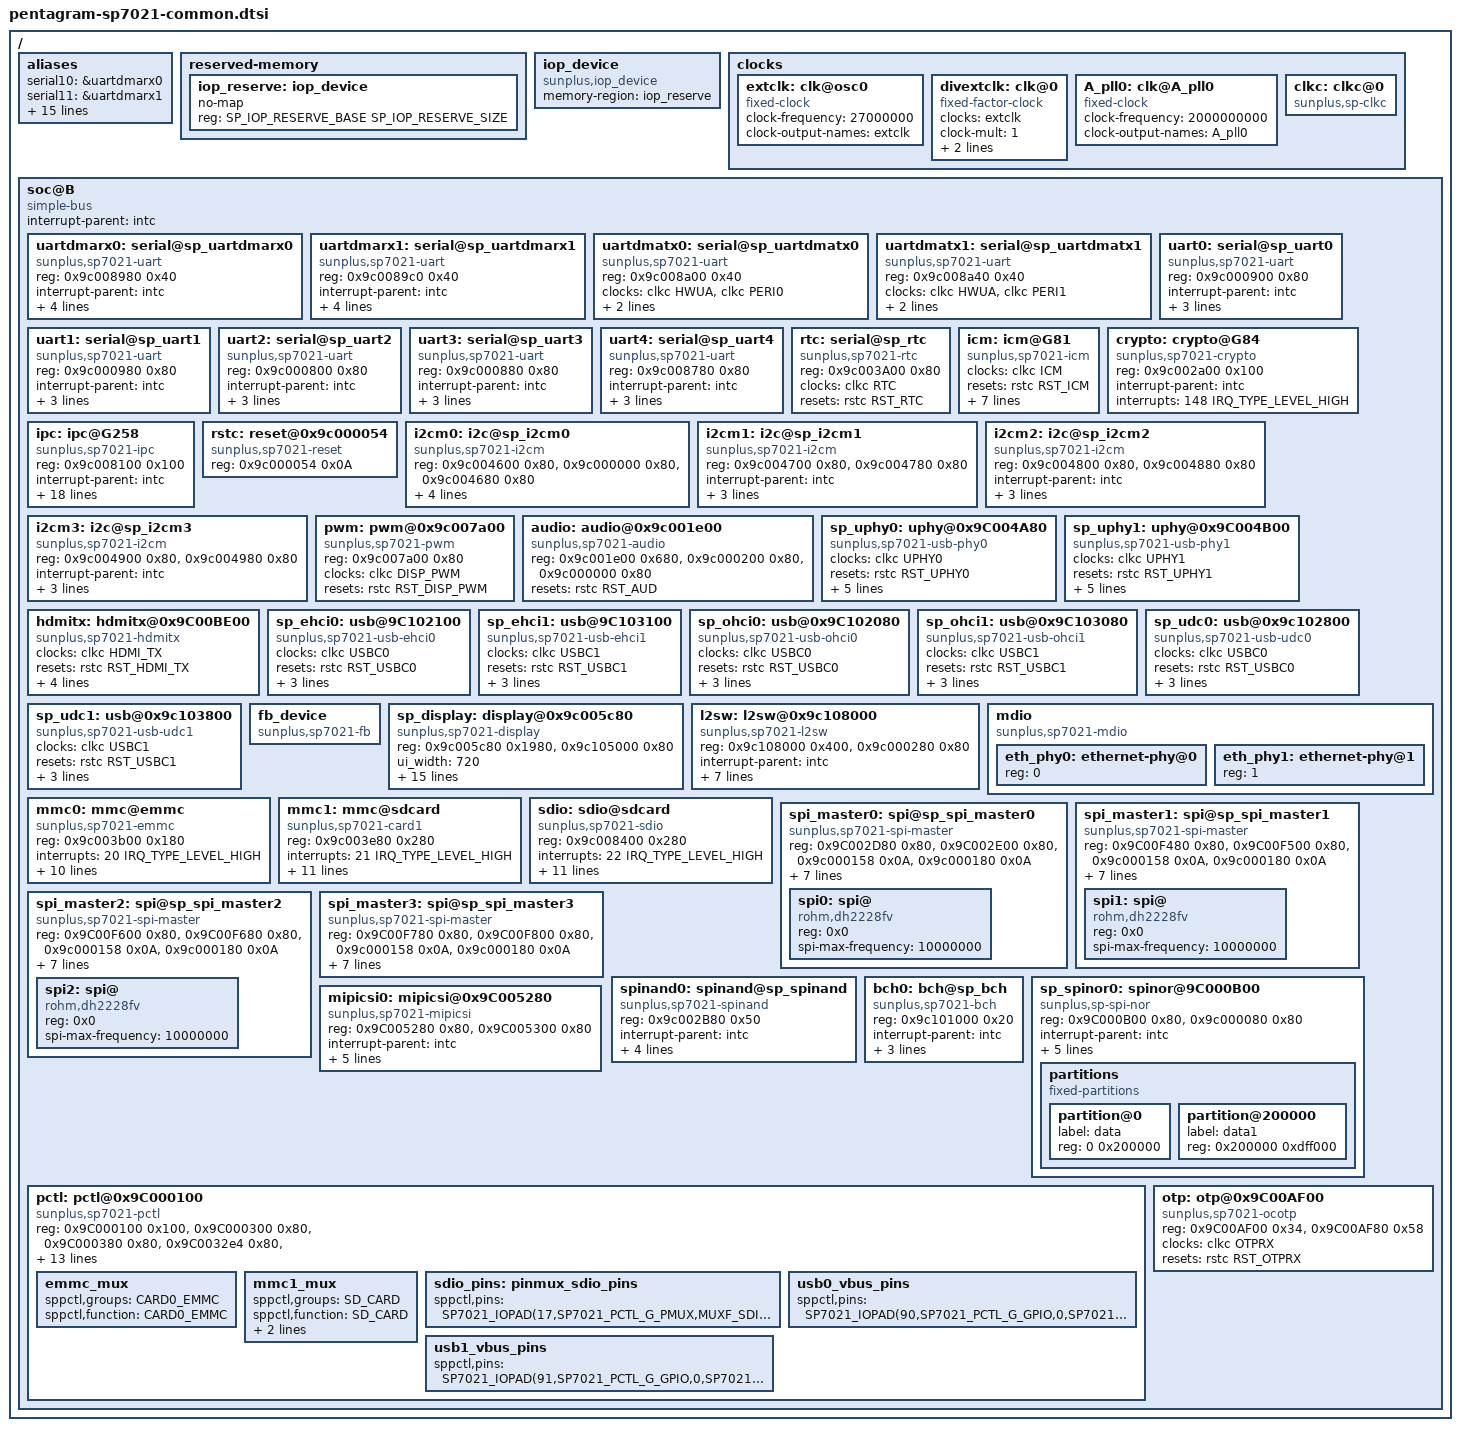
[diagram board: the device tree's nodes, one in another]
/dts-v1/;

#include "pentagram-sp7021-storage.dtsi"

#include <dt-bindings/clock/sp-q628.h>
#include <dt-bindings/memory/sp-q628-mem.h>
#include <dt-bindings/interrupt-controller/arm-gic.h>
#include <dt-bindings/interrupt-controller/sp-intc.h> /* SP_INTC_EXT_INT1 */
#include <dt-bindings/reset/sp-q628.h>
#include <dt-bindings/gpio/gpio.h>
#include <dt-bindings/pinctrl/sp7021.h>

#define ENABLE_DMARX0
#define ENABLE_DMARX1
#define ENABLE_DMATX0
#define ENABLE_DMATX1

/ {
	aliases {
#ifdef ENABLE_DMARX0
		serial10 = &uartdmarx0;
#endif
#ifdef ENABLE_DMARX1
		serial11 = &uartdmarx1;
#endif
#ifdef ENABLE_DMATX0
		serial20 = &uartdmatx0;
#endif
#ifdef ENABLE_DMATX1
		serial21 = &uartdmatx1;
#endif

		serial0 = &uart0;
		serial1 = &uart1;
		serial2 = &uart2;
		serial3 = &uart3;
		serial4 = &uart4;

/* Timer tests: */
/* 1. Enable device tree for timers. */
/* 2. Enable sp_timer_test in drivers/misc/Makefile */
#if 0

		stc0 = &sp_tmr_tst0;
		stc1 = &sp_tmr_tst1;
		stc2 = &sp_tmr_tst2;
		stc3 = &sp_tmr_tst3;

#endif

		i2c0 = &i2cm0;
		i2c1 = &i2cm1;
		i2c2 = &i2cm2;
		i2c3 = &i2cm3;

		spi0 = &spi_master0;
		spi1 = &spi_master1;
		spi2 = &spi_master2;
		spi3 = &spi_master3;

	};

	reserved-memory {
		#address-cells = <1>;
		#size-cells = <1>;
		ranges;

		iop_reserve: iop_device {
			no-map;
			reg = <SP_IOP_RESERVE_BASE SP_IOP_RESERVE_SIZE>;
		};
	};

	iop_device {
		compatible = "sunplus,iop_device";
		memory-region = <&iop_reserve>;
	};

	clocks {
		#address-cells = <1>;
		#size-cells = <1>;
		ranges;

		extclk: clk@osc0 {
			#clock-cells = <0>;
			compatible = "fixed-clock";
			clock-frequency = <27000000>;
			clock-output-names = "extclk";
		};

		divextclk: clk@0 {
			#clock-cells = <0>;
			compatible = "fixed-factor-clock";
			clocks  = <&extclk>;
			clock-mult = <1>;
			clock-div = <2>;
			clock-output-names = "extdivclk";
		};

		A_pll0: clk@A_pll0 {
			#clock-cells = <0>;
			compatible = "fixed-clock";
			clock-frequency = <2000000000>;
			clock-output-names = "A_pll0";
		};

		clkc: clkc@0 {
			#clock-cells = <1>;
			compatible = "sunplus,sp-clkc";
		};
	};

	soc@B {
		compatible = "simple-bus";
		#address-cells = <1>;
		#size-cells = <1>;
		ranges;

		interrupt-parent = <&intc>;

		/* B modules */
#if  0
		intc: interrupt-controller@G15 {
			compatible = "sunplus,sp-intc";
			interrupt-controller;
			#interrupt-cells = <2>;
			reg = <0x9c000780 0x80>, /* G15 */
			      <0x9c000a80 0x80>; /* G21 */
			interrupt-parent = <&gic>;
			interrupts = <GIC_SPI 5 IRQ_TYPE_LEVEL_HIGH>, /* EXT_INT0 */
				     <GIC_SPI 6 IRQ_TYPE_LEVEL_HIGH>; /* EXT_INT1 */
			ext0-mask = <0xf>; /* core0-3 */
			ext1-mask = <0xe>; /* core1-3 */
		};
#endif

#ifdef ENABLE_DMARX0
		/* DMA Rx for UARTx */
		uartdmarx0: serial@sp_uartdmarx0 {
			compatible = "sunplus,sp7021-uart";
			reg = <0x9c008980 0x40>;
			interrupt-parent = <&intc>;
			interrupts = <138 IRQ_TYPE_LEVEL_HIGH>;
			clocks = <&clkc UADMA>,
				 <&clkc PERI0>;
			clock-names = "UADMA",
				      "PERI0";
			resets = <&rstc RST_UADMA>;
			which-uart = <1>;
		};
#endif
#ifdef ENABLE_DMARX1
		uartdmarx1: serial@sp_uartdmarx1 {
			compatible = "sunplus,sp7021-uart";
			reg = <0x9c0089c0 0x40>;
			interrupt-parent = <&intc>;
			interrupts = <139 IRQ_TYPE_LEVEL_HIGH>;
			clocks = <&clkc UADMA>,
				 <&clkc PERI1>;
			clock-names = "UADMA",
				      "PERI1";
			resets = <&rstc RST_UADMA>;
			which-uart = <2>;
		};
#endif
#ifdef ENABLE_DMATX0
		/* DMA Tx for UARTx */
		uartdmatx0: serial@sp_uartdmatx0 {
			compatible = "sunplus,sp7021-uart";
			reg = <0x9c008a00 0x40>;
			clocks = <&clkc HWUA>,
				 <&clkc PERI0>;
			clock-names = "HWUA",
				      "PERI0";
			resets = <&rstc RST_UADMA>;
			which-uart = <1>;
		};
#endif
#ifdef ENABLE_DMATX1
		uartdmatx1: serial@sp_uartdmatx1 {
			compatible = "sunplus,sp7021-uart";
			reg = <0x9c008a40 0x40>;
			clocks = <&clkc HWUA>,
				 <&clkc PERI1>;
			clock-names = "HWUA",
				      "PERI1";
			resets = <&rstc RST_UADMA>;
			which-uart = <2>;
		};
#endif

		uart0: serial@sp_uart0 {
			compatible = "sunplus,sp7021-uart";
			reg = <0x9c000900 0x80>;
			interrupt-parent = <&intc>;
			interrupts = <53 IRQ_TYPE_LEVEL_HIGH>;
			clocks = <&clkc UA0>;
			resets = <&rstc RST_UA0>;
		};

		uart1: serial@sp_uart1 {
			compatible = "sunplus,sp7021-uart";
			reg = <0x9c000980 0x80>;
			interrupt-parent = <&intc>;
			interrupts = <54 IRQ_TYPE_LEVEL_HIGH>;
			clocks = <&clkc UA1>;
			resets = <&rstc RST_UA1>;
		};

		uart2: serial@sp_uart2 {
			compatible = "sunplus,sp7021-uart";
			reg = <0x9c000800 0x80>;
			interrupt-parent = <&intc>;
			interrupts = <55 IRQ_TYPE_LEVEL_HIGH>;
			clocks = <&clkc UA2>;
			resets = <&rstc RST_UA2>;
		};

		uart3: serial@sp_uart3 {
			compatible = "sunplus,sp7021-uart";
			reg = <0x9c000880 0x80>;
			interrupt-parent = <&intc>;
			interrupts = <56 IRQ_TYPE_LEVEL_HIGH>;
			clocks = <&clkc UA3>;
			resets = <&rstc RST_UA3>;
		};

		uart4: serial@sp_uart4 {
			compatible = "sunplus,sp7021-uart";
			reg = <0x9c008780 0x80>;
			interrupt-parent = <&intc>;
			interrupts = <134 IRQ_TYPE_LEVEL_HIGH>;
			clocks = <&clkc UA4>;
			resets = <&rstc RST_UA4>;
		};



		rtc: serial@sp_rtc {
			compatible = "sunplus,sp7021-rtc";
			reg = <0x9c003A00 0x80>;
			reg-names = "rtc_reg";
			clocks = <&clkc RTC>;
			resets = <&rstc RST_RTC>;
		};



		icm: icm@G81 {
			compatible = "sunplus,sp7021-icm";
			clocks = <&clkc ICM>;
			resets = <&rstc RST_ICM>;
			/* clken format: (group << 16) | (index << 8) | shift */
			clken = <0x00000a08>; /* 0.10.8 */
			reg = <0x9c002880 0x80>;
			interrupt-parent = <&intc>;
			interrupts =
				<92 IRQ_TYPE_EDGE_RISING>, /* icm0 */
				<93 IRQ_TYPE_EDGE_RISING>, /* icm1 */
				<94 IRQ_TYPE_EDGE_RISING>, /* icm2 */
				<95 IRQ_TYPE_EDGE_RISING>; /* icm3 */
		};

		crypto: crypto@G84 {
			compatible = "sunplus,sp7021-crypto";
			reg = <0x9c002a00 0x100>; /* G84 ~ G85 */
			interrupt-parent = <&intc>;
			interrupts = <148 IRQ_TYPE_LEVEL_HIGH>;
		};

		ipc: ipc@G258 {
			compatible = "sunplus,sp7021-ipc";
			reg = <0x9c008100 0x100>; /* G258 ~ G259 */
			interrupt-parent = <&intc>;
			interrupts =
				<182 IRQ_TYPE_EDGE_RISING>, /* ACHIPCPU0_DIRECT_INT0 */
				<183 IRQ_TYPE_EDGE_RISING>, /* ACHIPCPU0_DIRECT_INT1 */
				<184 IRQ_TYPE_EDGE_RISING>, /* ACHIPCPU0_DIRECT_INT2 */
				<185 IRQ_TYPE_EDGE_RISING>, /* ACHIPCPU0_DIRECT_INT3 */
				<186 IRQ_TYPE_EDGE_RISING>, /* ACHIPCPU0_DIRECT_INT4 */
				<187 IRQ_TYPE_EDGE_RISING>, /* ACHIPCPU0_DIRECT_INT5 */
				<188 IRQ_TYPE_EDGE_RISING>, /* ACHIPCPU0_DIRECT_INT6 */
				<189 IRQ_TYPE_EDGE_RISING>, /* ACHIPCPU0_DIRECT_INT7 */
				<190 IRQ_TYPE_EDGE_RISING>, /* A926_DIRECT_INT0 */
				<191 IRQ_TYPE_EDGE_RISING>, /* A926_DIRECT_INT1 */
				<192 IRQ_TYPE_EDGE_RISING>, /* A926_DIRECT_INT2 */
				<193 IRQ_TYPE_EDGE_RISING>, /* A926_DIRECT_INT3 */
				<194 IRQ_TYPE_EDGE_RISING>, /* A926_DIRECT_INT4 */
				<195 IRQ_TYPE_EDGE_RISING>, /* A926_DIRECT_INT5 */
				<196 IRQ_TYPE_EDGE_RISING>, /* A926_DIRECT_INT6 */
				<197 IRQ_TYPE_EDGE_RISING>, /* A926_DIRECT_INT7 */
				<198 IRQ_TYPE_EDGE_RISING>, /* ACHIPCPU0_INT */
				<199 IRQ_TYPE_EDGE_RISING>; /* A926_INT */
		};

/* Timer tests: */
/* 1. Enable device tree for timers. */
/* 2. Enable sp_timer_test in drivers/misc/Makefile */
#if 0
		sp_tmr_tst0: sp_tmr_tst@9c000600 {
			compatible = "sunplus,sp-tmr-tst";
			reg = <0x9c000600 0x80>;
			interrupt-parent = <&intc>;
			interrupts =
				<151 IRQ_TYPE_EDGE_RISING>, /* timer0 */
				<152 IRQ_TYPE_EDGE_RISING>, /* timer1 */
				<153 IRQ_TYPE_EDGE_RISING>, /* timer2 */
				<154 IRQ_TYPE_EDGE_RISING>; /* timer3 */
			clocks = <&clkc STC0>;
			resets = <&rstc RST_STC0>;
		};

		sp_tmr_tst1: sp_tmr_tst@9c003000 {
			compatible = "sunplus,sp-tmr-tst";
			reg = <0x9c003000 0x80>;
			interrupt-parent = <&intc>;
			interrupts =
				<155 IRQ_TYPE_EDGE_RISING>, /* timer0 */
				<156 IRQ_TYPE_EDGE_RISING>, /* timer1 */
				<157 IRQ_TYPE_EDGE_RISING>, /* timer2 */
				<158 IRQ_TYPE_EDGE_RISING>; /* timer3 */
			clocks = <&clkc STC_AV0>;
			resets = <&rstc RST_STC_AV0>;
		};

		sp_tmr_tst2: sp_tmr_tst@9c003080 {
			compatible = "sunplus,sp-tmr-tst";
			reg = <0x9c003080 0x80>;
			interrupt-parent = <&intc>;
			interrupts =
				<159 IRQ_TYPE_EDGE_RISING>, /* timer0 */
				<160 IRQ_TYPE_EDGE_RISING>, /* timer1 */
				<161 IRQ_TYPE_EDGE_RISING>, /* timer2 */
				<162 IRQ_TYPE_EDGE_RISING>; /* timer3 */
			clocks = <&clkc STC_AV1>;
			resets = <&rstc RST_STC_AV1>;
		};

		sp_tmr_tst3: sp_tmr_tst@9c003180 {
			compatible = "sunplus,sp-tmr-tst";
			reg = <0x9c003180 0x80>;
			interrupt-parent = <&intc>;
			interrupts =
				<164 IRQ_TYPE_EDGE_RISING>, /* timer0 */
				<165 IRQ_TYPE_EDGE_RISING>, /* timer1 */
				<166 IRQ_TYPE_EDGE_RISING>, /* timer2 */
				<167 IRQ_TYPE_EDGE_RISING>; /* timer3 */
			clocks = <&clkc STC_AV2>;
			resets = <&rstc RST_STC_AV2>;
		};
#endif

		rstc: reset@0x9c000054 {
			compatible = "sunplus,sp7021-reset";
			#reset-cells = <1>;
			reg = <0x9c000054 0x0A>;
			reg-names = "reset";
		};

		i2cm0: i2c@sp_i2cm0 {
			compatible = "sunplus,sp7021-i2cm";
			reg = <0x9c004600 0x80>, <0x9c000000 0x80>, <0x9c004680 0x80>;
			reg-names = "i2cm", "moon0", "i2cmdma";
			interrupt-parent = <&intc>;
			interrupts = <174 IRQ_TYPE_LEVEL_HIGH>;
			clocks = <&clkc I2CM0>;
			resets = <&rstc RST_I2CM0>;
		};

		i2cm1: i2c@sp_i2cm1 {
			compatible = "sunplus,sp7021-i2cm";
			reg = <0x9c004700 0x80>, <0x9c004780 0x80>;
			reg-names = "i2cm", "i2cmdma";
			interrupt-parent = <&intc>;
			interrupts = <175 IRQ_TYPE_LEVEL_HIGH>;
			clocks = <&clkc I2CM1>;
			resets = <&rstc RST_I2CM1>;
		};

		i2cm2: i2c@sp_i2cm2 {
			compatible = "sunplus,sp7021-i2cm";
			reg = <0x9c004800 0x80>, <0x9c004880 0x80>;
			reg-names = "i2cm", "i2cmdma";
			interrupt-parent = <&intc>;
			interrupts = <176 IRQ_TYPE_LEVEL_HIGH>;
			clocks = <&clkc I2CM2>;
			resets = <&rstc RST_I2CM2>;
		};

		i2cm3: i2c@sp_i2cm3 {
			compatible = "sunplus,sp7021-i2cm";
			reg = <0x9c004900 0x80>, <0x9c004980 0x80>;
			reg-names = "i2cm", "i2cmdma";
			interrupt-parent = <&intc>;
			interrupts = <177 IRQ_TYPE_LEVEL_HIGH>;
			clocks = <&clkc I2CM3>;
			resets = <&rstc RST_I2CM3>;
		};

		pwm: pwm@0x9c007a00 {
			#pwm-cells = <2>;
			compatible = "sunplus,sp7021-pwm";
			reg = <0x9c007a00 0x80>;
			clocks = <&clkc DISP_PWM>;
			resets = <&rstc RST_DISP_PWM>;
		 };

		audio: audio@0x9c001e00 {
			compatible = "sunplus,sp7021-audio";
			reg = <0x9c001e00 0x680>,<0x9c000200 0x80>,<0x9c000000 0x80>;
			reg-names = "audio", "moon4", "moon0";
			resets = <&rstc RST_AUD>;
		 };

		sp_uphy0: uphy@0x9C004A80 {
			compatible = "sunplus,sp7021-usb-phy0";
			clocks = <&clkc UPHY0>;
			resets = <&rstc RST_UPHY0>;
			reg = <0x9C004A80 0x80>;
			interrupt-parent = <&intc>;
			interrupts = <36 IRQ_TYPE_LEVEL_HIGH>;
		};

		sp_uphy1: uphy@0x9C004B00 {
			compatible = "sunplus,sp7021-usb-phy1";
			clocks = <&clkc UPHY1>;
			resets = <&rstc RST_UPHY1>;
			reg = <0x9C004B00 0x80>;
			interrupt-parent = <&intc>;
			interrupts = <37 IRQ_TYPE_LEVEL_HIGH>;
		};

		hdmitx: hdmitx@0x9C00BE00 {
			compatible = "sunplus,sp7021-hdmitx";
			clocks = <&clkc HDMI_TX>;
			resets = <&rstc RST_HDMI_TX>;
			reg = <0x9C00BE00 0x3FC>, <0x9C000200 0x80>, <0x9C000280 0x80>, <0x9C000080 0x80>;
			interrupt-parent = <&intc>;
			interrupts = <105 IRQ_TYPE_LEVEL_HIGH>;
		};

		sp_ehci0: usb@9C102100 {
			compatible = "sunplus,sp7021-usb-ehci0";
			clocks = <&clkc USBC0>;
			resets = <&rstc RST_USBC0>;
			reg = <0x9C102100 0x68>;
			interrupt-parent = <&intc>;
			interrupts = <14 IRQ_TYPE_LEVEL_HIGH>;
		};

		sp_ehci1: usb@9C103100 {
			compatible = "sunplus,sp7021-usb-ehci1";
			clocks = <&clkc USBC1>;
			resets = <&rstc RST_USBC1>;
			reg = <0x9C103100 0x68>;
			interrupt-parent = <&intc>;
			interrupts = <17 IRQ_TYPE_LEVEL_HIGH>;
		};

		sp_ohci0: usb@0x9C102080 {
			compatible = "sunplus,sp7021-usb-ohci0";
			clocks = <&clkc USBC0>;
			resets = <&rstc RST_USBC0>;
			reg = <0x9C102080 0x68>;
			interrupt-parent = <&intc>;
			interrupts = <15 IRQ_TYPE_LEVEL_HIGH>;
		};

		sp_ohci1: usb@0x9C103080 {
			compatible = "sunplus,sp7021-usb-ohci1";
			clocks = <&clkc USBC1>;
			resets = <&rstc RST_USBC1>;
			reg = <0x9C103080 0x68>;
			interrupt-parent = <&intc>;
			interrupts = <18 IRQ_TYPE_LEVEL_HIGH>;
		};

		sp_udc0: usb@0x9c102800 {
			compatible = "sunplus,sp7021-usb-udc0";
			clocks = <&clkc USBC0>;
			resets = <&rstc RST_USBC0>;
			reg = <0x9c102800 0x400>;
			interrupt-parent = <&intc>;
			interrupts = <13 IRQ_TYPE_LEVEL_HIGH>;
		};

		sp_udc1: usb@0x9c103800 {
			compatible = "sunplus,sp7021-usb-udc1";
			clocks = <&clkc USBC1>;
			resets = <&rstc RST_USBC1>;
			reg = <0x9c103800 0x400>;
			interrupt-parent = <&intc>;
			interrupts = <16 IRQ_TYPE_LEVEL_HIGH>;
		};

		fb_device {
			compatible = "sunplus,sp7021-fb";
		};

		sp_display: display@0x9c005c80 {
			compatible = "sunplus,sp7021-display";
			reg = <0x9c005c80 0x1980>,
				<0x9c105000 0x80>;
			ui_width = <720>;
			ui_height = <480>;
			ui_format = <0xe>;
				/* 0x2 = 8bpp (ARGB)
				 * 0x4 = YUY2
				 * 0x8 = RGB565
				 * 0x9 = ARGB1555
				 * 0xa = RGBA4444
				 * 0xb = ARGB4444
				 * 0xd = RGBA8888
				 * 0xe = ARGB8888 */
			interrupt-parent = <&intc>;
			interrupts = <0 (IRQ_TYPE_EDGE_RISING | SP_INTC_EXT_INT1)>,
				     <1 (IRQ_TYPE_EDGE_RISING | SP_INTC_EXT_INT1)>,
				     <4 (IRQ_TYPE_EDGE_RISING | SP_INTC_EXT_INT1)>,
				     <5 (IRQ_TYPE_EDGE_RISING | SP_INTC_EXT_INT1)>;
			clocks = <&clkc TGEN>,
				 <&clkc DMIX>,
				 <&clkc OSD0>,
				 <&clkc GPOST0>,
				 <&clkc VPOST>,
				 <&clkc DDFCH>,
				 <&clkc DVE>,
				 <&clkc HDMI_TX>;
			clock-names = "DISP_TGEN",
				      "DISP_DMIX",
				      "DISP_OSD0",
				      "DISP_GPOST0",
				      "DISP_VPOST",
				      "DISP_DDFCH",
				      "DISP_DVE",
				      "DISP_HDMI";
			resets = <&rstc RST_TGEN>,
				 <&rstc RST_DMIX>,
				 <&rstc RST_OSD0>,
				 <&rstc RST_GPOST0>,
				 <&rstc RST_VPOST>,
				 <&rstc RST_DDFCH>,
				 <&rstc RST_DVE>,
				 <&rstc RST_HDMI_TX>;
		};

		l2sw: l2sw@0x9c108000 {
			compatible = "sunplus,sp7021-l2sw";
			reg = <0x9c108000 0x400>, <0x9c000280 0x80>;
			reg-names = "l2sw", "moon5";
			interrupt-parent = <&intc>;
			interrupts = <66 IRQ_TYPE_LEVEL_HIGH>;
			clocks = <&clkc L2SW>;
			resets = <&rstc RST_L2SW>;
			mac-addr1 = <52>;
			mac-addr2 = <58>;
			phy-handle1 = <&eth_phy0>;
			phy-handle2 = <&eth_phy1>;
		};

		mdio {
			compatible = "sunplus,sp7021-mdio";
			#address-cells = <1>;
			#size-cells = <0>;
			eth_phy0: ethernet-phy@0 {
				reg = <0>;
			};
			eth_phy1: ethernet-phy@1 {
				reg = <1>;
			};
		};

		mmc0: mmc@emmc {
			compatible = "sunplus,sp7021-emmc";
			reg = <0x9c003b00 0x180>;
			interrupts = <20 IRQ_TYPE_LEVEL_HIGH>;
			clocks = <&clkc CARD_CTL0>;
			resets = <&rstc RST_CARD_CTL0>;
			bus-width = <8>;
			max-frequency = <52000000>;
			non-removable;
			disable-wp;
			cap-mmc-highspeed;
			mmc-ddr-3_3v;
			no-sdio;
			no-sd;
		};

		mmc1: mmc@sdcard {
			compatible = "sunplus,sp7021-card1";
			reg = <0x9c003e80 0x280>;
			interrupts = <21 IRQ_TYPE_LEVEL_HIGH>;
			clocks = <&clkc CARD_CTL1>;
			resets = <&rstc RST_CARD_CTL1>;
			pinctrl-names = "default";
			pinctrl-0 = <&mmc1_mux>;
			bus-width = <4>;
			max-frequency = <52000000>;
			cd-gpio = <&pctl 71 GPIO_ACTIVE_LOW>;
			broken-cd;
			disable-wp;
			cap-sd-highspeed;
			no-sdio;
			no-mmc;
		};

		sdio: sdio@sdcard {
			compatible = "sunplus,sp7021-sdio";
			reg = <0x9c008400 0x280>;
			interrupts = <22 IRQ_TYPE_LEVEL_HIGH>;
			clocks = <&clkc CARD_CTL4>;
			resets = <&rstc RST_CARD_CTL4>;
			pinctrl-names = "default";
			pinctrl-0 = <&sdio_pins>;
			bus-width = <4>;
			max-frequency = <52000000>;
			non-removable;
			disable-wp;
			cap-sd-highspeed;
			cap-sdio-irq;
			no-sd;
			no-mmc;
		};

		spi_master0: spi@sp_spi_master0 {
			compatible = "sunplus,sp7021-spi-master";
			reg = <0x9C002D80 0x80>,<0x9C002E00 0x80>, <0x9c000158 0x0A>, <0x9c000180 0x0A>;
			reg-names = "spi_master", "spi_slave" , "grp2_sft" , "grp3_sft";
			interrupt-parent = <&intc>;
			interrupt-names = "dma_w_intr",
					  "mas_risc_intr",
					  "slave_risc_intr";
			interrupts = <144 IRQ_TYPE_LEVEL_HIGH>,
				     <146 IRQ_TYPE_LEVEL_HIGH>,
				     <145 IRQ_TYPE_LEVEL_HIGH>;
			clocks = <&clkc SPI_COMBO_0>;
			clock-names = "sys_pll";
			resets = <&rstc RST_SPI_COMBO_0>;
			spi-max-frequency = <10000000>;
			#address-cells = <1>;
			#size-cells = <0>;
			spi0: spi@ {
				compatible = "rohm,dh2228fv";
				reg = <0x0>;
				spi-max-frequency = <10000000>;
			};
		};

		spi_master1: spi@sp_spi_master1 {
			compatible = "sunplus,sp7021-spi-master";
			reg = <0x9C00F480 0x80>,<0x9C00F500 0x80>, <0x9c000158 0x0A>, <0x9c000180 0x0A>;
			reg-names = "spi_master", "spi_slave" , "grp2_sft" , "grp3_sft";
			interrupt-parent = <&intc>;
			interrupt-names = "dma_w_intr",
					  "mas_risc_intr",
					  "slave_risc_intr";
			interrupts = <67 IRQ_TYPE_LEVEL_HIGH>,
				     <69 IRQ_TYPE_LEVEL_HIGH>,
				     <68 IRQ_TYPE_LEVEL_HIGH>;
			clocks = <&clkc SPI_COMBO_1>;
			clock-names = "sys_pll";
			resets = <&rstc RST_SPI_COMBO_1>;
			spi-max-frequency = <10000000>;
			#address-cells = <1>;
			#size-cells = <0>;
			spi1: spi@ {
				compatible = "rohm,dh2228fv";
				reg = <0x0>;
				spi-max-frequency = <10000000>;
			};
		};

		spi_master2: spi@sp_spi_master2 {
			compatible = "sunplus,sp7021-spi-master";
			reg = <0x9C00F600 0x80>,<0x9C00F680 0x80>, <0x9c000158 0x0A>, <0x9c000180 0x0A>;
			reg-names = "spi_master", "spi_slave" , "grp2_sft" , "grp3_sft";
			interrupt-parent = <&intc>;
			interrupt-names = "dma_w_intr",
					  "mas_risc_intr",
					  "slave_risc_intr";
			interrupts = <70 IRQ_TYPE_LEVEL_HIGH>,
				     <72 IRQ_TYPE_LEVEL_HIGH>,
				     <71 IRQ_TYPE_LEVEL_HIGH>;
			clocks = <&clkc SPI_COMBO_2>;
			clock-names = "sys_pll";
			resets = <&rstc RST_SPI_COMBO_2>;
			spi-max-frequency = <10000000>;
			#address-cells = <1>;
			#size-cells = <0>;
			spi2: spi@ {
				compatible = "rohm,dh2228fv";
				reg = <0x0>;
				spi-max-frequency = <10000000>;
			};
		};

		spi_master3: spi@sp_spi_master3 {
			compatible = "sunplus,sp7021-spi-master";
			reg = <0x9C00F780 0x80>,<0x9C00F800 0x80>, <0x9c000158 0x0A>, <0x9c000180 0x0A>;
			reg-names = "spi_master", "spi_slave" , "grp2_sft" , "grp3_sft";
			interrupt-parent = <&intc>;
			interrupt-names = "dma_w_intr",
					  "mas_risc_intr",
					  "slave_risc_intr";
			interrupts = <73 IRQ_TYPE_LEVEL_HIGH>,
				     <75 IRQ_TYPE_LEVEL_HIGH>,
				     <74 IRQ_TYPE_LEVEL_HIGH>;
			clocks = <&clkc SPI_COMBO_3>;
			clock-names = "sys_pll";
			resets = <&rstc RST_SPI_COMBO_3>;
			spi-max-frequency = <10000000>;
		};

		spinand0: spinand@sp_spinand {
			compatible = "sunplus,sp7021-spinand";
			reg = <0x9c002B80 0x50>;
			interrupt-parent = <&intc>;
			interrupts = <149 IRQ_TYPE_LEVEL_HIGH>;
			linux,part-probe = "ofpart", "sunplus_part";
			clocks = <&clkc SPIND>;
			resets = <&rstc RST_SPIND>;
		};

		bch0: bch@sp_bch {
			compatible = "sunplus,sp7021-bch";
			reg = <0x9c101000 0x20>;
			interrupt-parent = <&intc>;
			interrupts = <58 IRQ_TYPE_LEVEL_HIGH>;
			clocks = <&clkc BCH>;
			resets = <&rstc RST_BCH>;
		};

		sp_spinor0: spinor@9C000B00 {
			compatible = "sunplus,sp-spi-nor";
			reg = <0x9C000B00 0x80>,<0x9c000080 0x80>;
			interrupt-parent = <&intc>;
			interrupts = <143 IRQ_TYPE_LEVEL_HIGH>;
			clocks = <&clkc SPIFL>;
			resets = <&rstc RST_SPIFL>;
			spi-max-frequency = <50000000>;
			spi-chip-selection = <0>;
			partitions {
				compatible = "fixed-partitions";
				#address-cells = <1>;
				#size-cells = <1>;
				partition@0 {
					label = "data";
					reg = <0 0x200000>;
				};
				partition@200000 {
					label = "data1";
					reg = <0x200000 0xdff000>;
				};
			};
		};

		mipicsi0: mipicsi@0x9C005280 {
			compatible = "sunplus,sp7021-mipicsi";
			reg = <0x9C005280 0x80>, <0x9C005300 0x80>;
			reg-names = "mipicsi", "csiiw";
			interrupt-parent = <&intc>;
			interrupts = <49 IRQ_TYPE_EDGE_RISING>,
				     <50 IRQ_TYPE_EDGE_RISING>;
			clocks = <&clkc MIPICSI0>, <&clkc CSIIW0>;
			clock-names = "clk_mipicsi", "clk_csiiw";
			resets = <&rstc RST_MIPICSI0>, <&rstc RST_CSIIW0>;
			reset-names = "rstc_mipicsi", "rstc_csiiw";
			i2c-id = <1>;
		};
/*
		mipicsi1: mipicsi@0x9C005380 {
			compatible = "sunplus,sp7021-mipicsi";
			reg = <0x9C005380 0x80>, <0x9C005400 0x80>;
			reg-names = "mipicsi", "csiiw";
			interrupt-parent = <&intc>;
			interrupts = <51 IRQ_TYPE_LEVEL_HIGH>,
				     <52 IRQ_TYPE_LEVEL_HIGH>;
			clocks = <&clkc MIPICSI1>, <&clkc CSIIW1>;
			clock-names = "clk_mipicsi", "clk_csiiw";
			resets = <&rstc RST_MIPICSI1>, <&rstc RST_CSIIW1>;
			reset-names = "rstc_mipicsi", "rstc_csiiw";
			i2c-id = <2>;
		};
*/
		pctl: pctl@0x9C000100 {
			compatible = "sunplus,sp7021-pctl";
			reg = <0x9C000100 0x100>, <0x9C000300 0x80>, <0x9C000380 0x80>, <0x9C0032e4 0x80>, <0x9C000080 0x20>;
			gpio-controller;
			#gpio-cells = <2>;
			interrupt-parent = <&intc>;
			interrupts =
				<120 IRQ_TYPE_LEVEL_HIGH>,
				<121 IRQ_TYPE_LEVEL_HIGH>,
				<122 IRQ_TYPE_LEVEL_HIGH>,
				<123 IRQ_TYPE_LEVEL_HIGH>,
				<124 IRQ_TYPE_LEVEL_HIGH>,
				<125 IRQ_TYPE_LEVEL_HIGH>,
				<126 IRQ_TYPE_LEVEL_HIGH>,
				<127 IRQ_TYPE_LEVEL_HIGH>;
			clocks = <&clkc GPIO>;
			resets = <&rstc RST_GPIO>;
			emmc_mux: emmc_mux {
				sppctl,groups = "CARD0_EMMC";
				sppctl,function = "CARD0_EMMC";
			};
			mmc1_mux: mmc1_mux {
				sppctl,groups = "SD_CARD";
				sppctl,function = "SD_CARD";
				sppctl,pins = < SP7021_IOPAD(71,SP7021_PCTL_G_GPIO,0,0) >;
			};
			sdio_pins: pinmux_sdio_pins {
				sppctl,pins = <
					SP7021_IOPAD(17,SP7021_PCTL_G_PMUX,MUXF_SDIO_D1,0)
					SP7021_IOPAD(19,SP7021_PCTL_G_PMUX,MUXF_SDIO_D0,0)
					SP7021_IOPAD(21,SP7021_PCTL_G_PMUX,MUXF_SDIO_CLK,0)
					SP7021_IOPAD(23,SP7021_PCTL_G_PMUX,MUXF_SDIO_CMD,0)
					SP7021_IOPAD(25,SP7021_PCTL_G_PMUX,MUXF_SDIO_D3,0)
					SP7021_IOPAD(27,SP7021_PCTL_G_PMUX,MUXF_SDIO_D2,0) >;
			};
		};

		otp: otp@0x9C00AF00 {
			compatible = "sunplus,sp7021-ocotp";
			reg = <0x9C00AF00 0x34>, <0x9C00AF80 0x58>;
			reg-names = "hb_gpio", "otprx";
			clocks = <&clkc OTPRX>;
			resets = <&rstc RST_OTPRX>;
		};
	};
};

&sp_uphy0 {
  pinctrl-names = "default";
  pinctrl-0 = <&usb0_vbus_pins>;
  vbus-gpio = <&pctl 90 GPIO_ACTIVE_HIGH>;
};

&sp_uphy1 {
  pinctrl-names = "default";
  pinctrl-0 = <&usb1_vbus_pins>;
  vbus-gpio = <&pctl 91 GPIO_ACTIVE_HIGH>;
};

&pctl {
	usb0_vbus_pins: usb0_vbus_pins {
		sppctl,pins = <
		  SP7021_IOPAD(90,SP7021_PCTL_G_GPIO,0,SP7021_PCTL_L_OUT)
		>;
	};
	usb1_vbus_pins: usb1_vbus_pins {
		sppctl,pins = <
		  SP7021_IOPAD(91,SP7021_PCTL_G_GPIO,0,SP7021_PCTL_L_OUT)
		>;
	};
};

